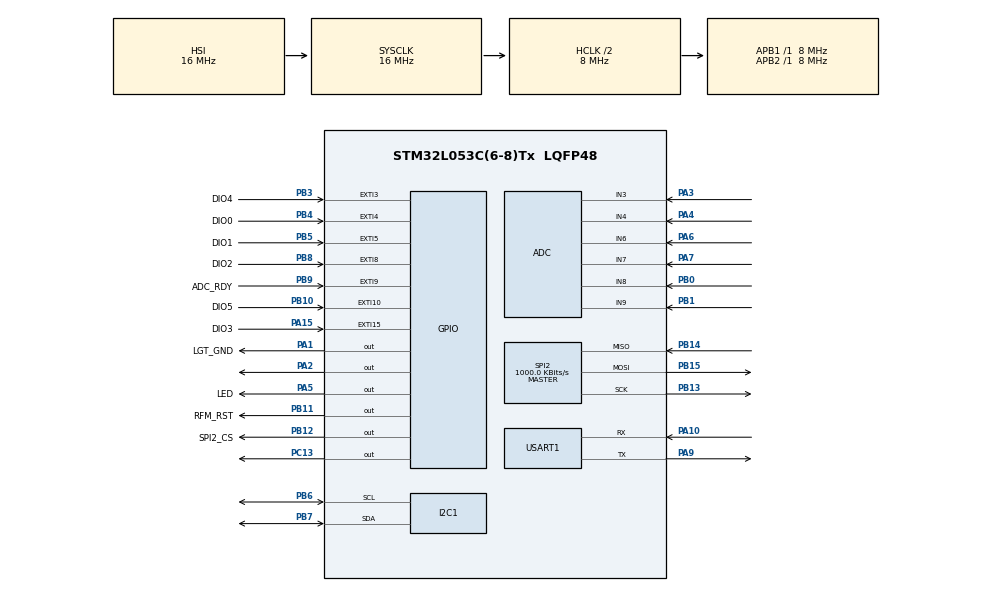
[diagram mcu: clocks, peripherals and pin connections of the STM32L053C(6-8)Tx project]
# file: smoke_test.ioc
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I2C1.Analog_Filter=I2C_ANALOGFILTER_ENABLE
I2C1.Speed=100
I2C1.Timing=0x2000090E
Mcu.Family=STM32L0
Mcu.Name=STM32L053C(6-8)Tx
Mcu.Package=LQFP48
NVIC.EXTI4_15_IRQn=true\:0\:0\:false\:false\:true
NVIC.RTC_IRQn=true\:0\:0\:true\:false\:true
PA1.GPIO_Label=LGT_GND
PA1.Signal=GPIO_Output
PA10.Mode=Asynchronous
PA10.Signal=USART1_RX
PA13.Mode=Serial_Wire
PA13.Signal=SYS_SWDIO
PA14.Mode=Serial_Wire
PA14.Signal=SYS_SWCLK
PA15.GPIO_Label=DIO3
PA15.Signal=GPXTI15
PA2.Signal=GPIO_Output
PA3.Mode=IN3
PA3.Signal=ADC_IN3
PA4.Mode=IN4
PA4.Signal=ADC_IN4
PA5.GPIO_Label=LED
PA5.Signal=GPIO_Output
PA6.Mode=IN6
PA6.Signal=ADC_IN6
PA7.Mode=IN7
PA7.Signal=ADC_IN7
PA9.Mode=Asynchronous
PA9.Signal=USART1_TX
PB0.Mode=IN8
PB0.Signal=ADC_IN8
PB1.Mode=IN9
PB1.Signal=ADC_IN9
PB10.GPIO_Label=DIO5
PB10.Signal=GPXTI10
PB11.GPIO_Label=RFM_RST
PB11.Signal=GPIO_Output
PB12.GPIO_Label=SPI2_CS
PB12.Signal=GPIO_Output
PB13.Mode=Full_Duplex_Master
PB13.Signal=SPI2_SCK
PB14.Mode=Full_Duplex_Master
PB14.Signal=SPI2_MISO
PB15.Mode=Full_Duplex_Master
PB15.Signal=SPI2_MOSI
PB3.GPIO_Label=DIO4
PB3.Signal=GPXTI3
PB4.GPIO_Label=DIO0
PB4.Signal=GPXTI4
PB5.GPIO_Label=DIO1
PB5.Signal=GPXTI5
PB6.Mode=I2C
PB6.Signal=I2C1_SCL
PB7.Mode=I2C
PB7.Signal=I2C1_SDA
PB8.GPIO_Label=DIO2
PB8.Signal=GPXTI8
PB9.GPIO_Label=ADC_RDY
PB9.Signal=GPXTI9
PC13.Signal=GPIO_Output
ProjectManager.HeapSize=0x200
ProjectManager.StackSize=0x400
ProjectManager.TargetToolchain=SW4STM32
RCC.AHBCLKDivider=RCC_SYSCLK_DIV2
RCC.AHBFreq_Value=8000000
RCC.APB1Freq_Value=8000000
RCC.APB1TimFreq_Value=8000000
RCC.APB2Freq_Value=8000000
RCC.APB2TimFreq_Value=8000000
RCC.HCLKFreq_Value=8000000
RCC.HSE_VALUE=8000000
RCC.HSI16_VALUE=16000000
RCC.HSI48_VALUE=48000000
RCC.HSI_VALUE=16000000
RCC.LSE_VALUE=32768
RCC.MSI_VALUE=2097000
RCC.SYSCLKFreq_VALUE=16000000
RCC.SYSCLKSource=RCC_SYSCLKSOURCE_HSI
RCC.VCOOutputFreq_Value=48000000
RTC.WakeUpClock-WakeUp=RTC_WAKEUPCLOCK_CK_SPRE_16BITS
SPI2.BaudRatePrescaler=SPI_BAUDRATEPRESCALER_8
SPI2.CLKPhase=SPI_PHASE_1EDGE
SPI2.CLKPolarity=SPI_POLARITY_LOW
SPI2.CalculateBaudRate=1000.0 KBits/s
SPI2.Direction=SPI_DIRECTION_2LINES
SPI2.Mode=SPI_MODE_MASTER
SPI2.VirtualType=VM_MASTER
USART1.VirtualMode-Asynchronous=VM_ASYNC
USART1.WordLength=WORDLENGTH_8B
VP_ADC_TempSens_Input.Mode=IN-TempSens
VP_ADC_Vref_Input.Mode=IN-Vrefint
VP_RTC_VS_RTC_Activate.Mode=RTC_Enabled
VP_RTC_VS_RTC_Calendar.Mode=RTC_Calendar
VP_RTC_VS_RTC_WakeUp_intern.Mode=WakeUp
board=smoke_test

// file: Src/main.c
/**
  ******************************************************************************
  * File Name          : main.c
  * Description        : Main program body
  ******************************************************************************
  ** This notice applies to any and all portions of this file
  * that are not between comment pairs USER CODE BEGIN and
  * USER CODE END. Other portions of this file, whether
  * inserted by the user or by software development tools
  * are owned by their respective copyright owners.
  *
  * COPYRIGHT(c) 2017 STMicroelectronics
  *
  * Redistribution and use in source and binary forms, with or without modification,
  * are permitted provided that the following conditions are met:
  *   1. Redistributions of source code must retain the above copyright notice,
  *      this list of conditions and the following disclaimer.
  *   2. Redistributions in binary form must reproduce the above copyright notice,
  *      this list of conditions and the following disclaimer in the documentation
  *      and/or other materials provided with the distribution.
  *   3. Neither the name of STMicroelectronics nor the names of its contributors
  *      may be used to endorse or promote products derived from this software
  *      without specific prior written permission.
  *
  * THIS SOFTWARE IS PROVIDED BY THE COPYRIGHT HOLDERS AND CONTRIBUTORS "AS IS"
  * AND ANY EXPRESS OR IMPLIED WARRANTIES, INCLUDING, BUT NOT LIMITED TO, THE
  * IMPLIED WARRANTIES OF MERCHANTABILITY AND FITNESS FOR A PARTICULAR PURPOSE ARE
  * DISCLAIMED. IN NO EVENT SHALL THE COPYRIGHT HOLDER OR CONTRIBUTORS BE LIABLE
  * FOR ANY DIRECT, INDIRECT, INCIDENTAL, SPECIAL, EXEMPLARY, OR CONSEQUENTIAL
  * DAMAGES (INCLUDING, BUT NOT LIMITED TO, PROCUREMENT OF SUBSTITUTE GOODS OR
  * SERVICES; LOSS OF USE, DATA, OR PROFITS; OR BUSINESS INTERRUPTION) HOWEVER
  * CAUSED AND ON ANY THEORY OF LIABILITY, WHETHER IN CONTRACT, STRICT LIABILITY,
  * OR TORT (INCLUDING NEGLIGENCE OR OTHERWISE) ARISING IN ANY WAY OUT OF THE USE
  * OF THIS SOFTWARE, EVEN IF ADVISED OF THE POSSIBILITY OF SUCH DAMAGE.
  *
  ******************************************************************************
  */
#include "main.h"
#include "stm32l0xx_hal.h"
#include "adc.h"
#include "i2c.h"
#include "rtc.h"
#include "spi.h"
#include "usart.h"
#include "gpio.h"

/* USER CODE BEGIN Includes */
#include "string.h"
#include "ads1015.h"

/* USER CODE END Includes */

/* USER CODE BEGIN PV */
/* Private variables ---------------------------------------------------------*/

/* USER CODE END PV */

void SystemClock_Config(void);

/* USER CODE BEGIN PFP */
/* Private function prototypes -----------------------------------------------*/

/* USER CODE END PFP */

int main(void)
{

  /* MCU Configuration----------------------------------------------------------*/

  /* Reset of all peripherals, Initializes the Flash interface and the Systick. */
  HAL_Init();

  /* Configure the system clock */
  SystemClock_Config();

  /* Initialize all configured peripherals */
  MX_GPIO_Init();
  MX_ADC_Init();
  MX_I2C1_Init();
  MX_RTC_Init();
  MX_USART1_UART_Init();
  MX_SPI2_Init();

  /* USER CODE BEGIN 2 */

  /* Buffer used for transmission on USART1 */
  char tx1_buffer[80];
  uint8_t count = 0;

  /* USER CODE END 2 */

  /* Infinite loop */
  while (1)
  {

  /* USER CODE BEGIN 3 */

      sprintf(tx1_buffer, "Count is %d\n", count);
      HAL_UART_Transmit(&huart1, (uint8_t*) tx1_buffer, strlen(tx1_buffer), 5000);
      count++;

      uint16_t adc_val = ADS1015_SingleEnded(&hi2c1, ADS1015_ADDRESS, 3, ADS1015_GAIN_ONE);
      sprintf(tx1_buffer, "adc_val: %d\n", adc_val);
      HAL_UART_Transmit(&huart1, (uint8_t*) tx1_buffer, strlen(tx1_buffer), 5000);

      //ADS1015_writeRegister(&hi2c1, ADS1015_ADDRESS, ADS1015_REG_POINTER_CONFIG, ADS1015_REG_CONFIG_MUX_SINGLE_3);

      //HAL_Delay(ADS1015_CONVERSIONDELAY);

//      uint16_t adc_val = ADS1015_readRegister(&hi2c1, ADS1015_ADDRESS, ADS1015_REG_POINTER_CONVERT);
//sprintf(tx1_buffer, "adc_val: %04X\n", adc_val);
//      HAL_UART_Transmit(&huart1, (uint8_t*) tx1_buffer, strlen(tx1_buffer), 5000);

      HAL_GPIO_TogglePin(GPIOA, LED_Pin);
      HAL_Delay(1000);

  }
  /* USER CODE END 3 */

}

/** System Clock Configuration
*/
void SystemClock_Config(void)
{

  RCC_OscInitTypeDef RCC_OscInitStruct;
  RCC_ClkInitTypeDef RCC_ClkInitStruct;
  RCC_PeriphCLKInitTypeDef PeriphClkInit;

    /**Configure the main internal regulator output voltage
    */
  __HAL_PWR_VOLTAGESCALING_CONFIG(PWR_REGULATOR_VOLTAGE_SCALE1);

    /**Initializes the CPU, AHB and APB busses clocks
    */
  RCC_OscInitStruct.OscillatorType = RCC_OSCILLATORTYPE_HSI|RCC_OSCILLATORTYPE_LSI;
  RCC_OscInitStruct.HSIState = RCC_HSI_ON;
  RCC_OscInitStruct.HSICalibrationValue = 16;
  RCC_OscInitStruct.LSIState = RCC_LSI_ON;
  RCC_OscInitStruct.PLL.PLLState = RCC_PLL_NONE;
  if (HAL_RCC_OscConfig(&RCC_OscInitStruct) != HAL_OK)
  {
    _Error_Handler(__FILE__, __LINE__);
  }

    /**Initializes the CPU, AHB and APB busses clocks
    */
  RCC_ClkInitStruct.ClockType = RCC_CLOCKTYPE_HCLK|RCC_CLOCKTYPE_SYSCLK
                              |RCC_CLOCKTYPE_PCLK1|RCC_CLOCKTYPE_PCLK2;
  RCC_ClkInitStruct.SYSCLKSource = RCC_SYSCLKSOURCE_HSI;
  RCC_ClkInitStruct.AHBCLKDivider = RCC_SYSCLK_DIV2;
  RCC_ClkInitStruct.APB1CLKDivider = RCC_HCLK_DIV1;
  RCC_ClkInitStruct.APB2CLKDivider = RCC_HCLK_DIV1;

  if (HAL_RCC_ClockConfig(&RCC_ClkInitStruct, FLASH_LATENCY_0) != HAL_OK)
  {
    _Error_Handler(__FILE__, __LINE__);
  }

  PeriphClkInit.PeriphClockSelection = RCC_PERIPHCLK_USART1|RCC_PERIPHCLK_I2C1
                              |RCC_PERIPHCLK_RTC;
  PeriphClkInit.Usart1ClockSelection = RCC_USART1CLKSOURCE_PCLK2;
  PeriphClkInit.I2c1ClockSelection = RCC_I2C1CLKSOURCE_PCLK1;
  PeriphClkInit.RTCClockSelection = RCC_RTCCLKSOURCE_LSI;
  if (HAL_RCCEx_PeriphCLKConfig(&PeriphClkInit) != HAL_OK)
  {
    _Error_Handler(__FILE__, __LINE__);
  }

    /**Configure the Systick interrupt time
    */
  HAL_SYSTICK_Config(HAL_RCC_GetHCLKFreq()/1000);

    /**Configure the Systick
    */
  HAL_SYSTICK_CLKSourceConfig(SYSTICK_CLKSOURCE_HCLK);

  /* SysTick_IRQn interrupt configuration */
  HAL_NVIC_SetPriority(SysTick_IRQn, 0, 0);
}

void _Error_Handler(char * file, int line)
{
  while(1)
  {
  }
}

/************************ (C) COPYRIGHT STMicroelectronics *****END OF FILE****/
